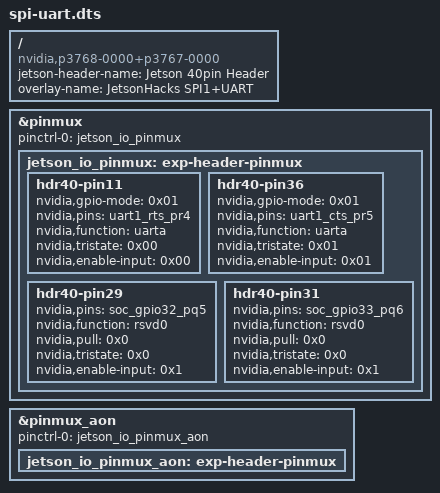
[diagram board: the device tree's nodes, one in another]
/dts-v1/;
/plugin/;

/ {
	jetson-header-name = "Jetson 40pin Header";
	overlay-name = "JetsonHacks SPI1+UART";
	compatible = "nvidia,p3768-0000+p3767-0000",
	             "nvidia,p3768-0000+p3767-0001",
	             "nvidia,p3768-0000+p3767-0003",
	             "nvidia,p3768-0000+p3767-0004",
	             "nvidia,p3768-0000+p3767-0005",
	             "nvidia,p3768-0000+p3767-0000-super",
	             "nvidia,p3768-0000+p3767-0001-super",
	             "nvidia,p3768-0000+p3767-0003-super",
	             "nvidia,p3768-0000+p3767-0004-super",
	             "nvidia,p3768-0000+p3767-0005-super",
	             "nvidia,p3509-0000+p3767-0000",
	             "nvidia,p3509-0000+p3767-0001",
	             "nvidia,p3509-0000+p3767-0003",
	             "nvidia,p3509-0000+p3767-0004",
	             "nvidia,p3509-0000+p3767-0005";

	fragment@0 {
		target = <&pinmux>;

		__overlay__ {
			pinctrl-names = "default";
			pinctrl-0 = <&jetson_io_pinmux>;

			jetson_io_pinmux: exp-header-pinmux {

				hdr40-pin11 {
					nvidia,gpio-mode = <0x01>;
					nvidia,pins = "uart1_rts_pr4";
					nvidia,function = "uarta";
					nvidia,tristate = <0x00>;
					nvidia,enable-input = <0x00>;
				};

				hdr40-pin36 {
					nvidia,gpio-mode = <0x01>;
					nvidia,pins = "uart1_cts_pr5";
					nvidia,function = "uarta";
					nvidia,tristate = <0x01>;
					nvidia,enable-input = <0x01>;
				};

				hdr40-pin29 {
                    nvidia,pins = "soc_gpio32_pq5";
                    nvidia,function = "rsvd0";
                    nvidia,pull = <0x0>;           /* 0=none, 1=down, 2=up */
                    nvidia,tristate = <0x0>;       /* 0=drive, 1=tristate */
                    nvidia,enable-input = <0x1>;   /* 0=output only, 1=input enabled */
                };

				hdr40-pin31 {
                    nvidia,pins = "soc_gpio33_pq6";
                    nvidia,function = "rsvd0";
                    nvidia,pull = <0x0>;           /* 0=none, 1=down, 2=up */
                    nvidia,tristate = <0x0>;       /* 0=drive, 1=tristate */
                    nvidia,enable-input = <0x1>;   /* 0=output only, 1=input enabled */
                };



			};
		};
	};

	fragment@1 {
		target = <&pinmux_aon>;

		__overlay__ {
			pinctrl-names = "default";
			pinctrl-0 = <&jetson_io_pinmux_aon>;

			jetson_io_pinmux_aon: exp-header-pinmux {
			};
		};
	};
};
